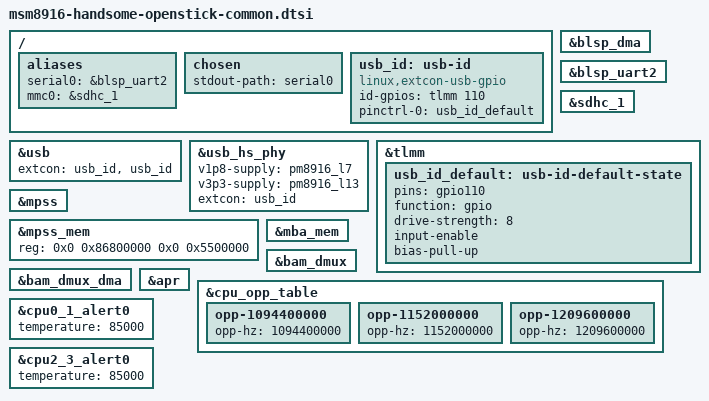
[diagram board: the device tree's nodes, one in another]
// SPDX-License-Identifier: GPL-2.0-only
/*
 * Common definitions for Handsome OpenStick family MSM8916 devices.
 *
 * Based on HandsomeMod 5.10 patches by HandsomeYingyan
 * <handsomeyingyan@gmail.com>, adapted for mainline:
 *   blsp1_uart2 -> blsp_uart2, pronto -> wcnss, msmgpio -> tlmm,
 *   smd_rpm_regulators -> pm8916_rpm_regulators (voltages now upstreamed).
 *
 * Modem is enabled for data only (bam-dmux); voice call services
 * (q6voiced/q6mvm/q6cvp/q6cvs) are not yet available in mainline.
 */

#include "msm8916-pm8916.dtsi"
#include <dt-bindings/gpio/gpio.h>
#include <dt-bindings/input/input.h>

/ {
	aliases {
		serial0 = &blsp_uart2;
		mmc0 = &sdhc_1;
	};

	chosen {
		stdout-path = "serial0";
	};

	usb_id: usb-id {
		compatible = "linux,extcon-usb-gpio";
		id-gpios = <&tlmm 110 GPIO_ACTIVE_HIGH>;
		pinctrl-names = "default";
		pinctrl-0 = <&usb_id_default>;
	};
};

&blsp_dma {
	status = "okay";
};

&blsp_uart2 {
	status = "okay";
};

&sdhc_1 {
	status = "okay";
};

&usb {
	status = "okay";
	extcon = <&usb_id>, <&usb_id>;
};

&usb_hs_phy {
	v1p8-supply = <&pm8916_l7>;
	v3p3-supply = <&pm8916_l13>;
	extcon = <&usb_id>;
};

&tlmm {
	usb_id_default: usb-id-default-state {
		pins = "gpio110";
		function = "gpio";

		drive-strength = <8>;
		input-enable;
		bias-pull-up;
	};
};

/* Modem (Hexagon) for mobile data */
&mpss {
	status = "okay";
};

&mpss_mem {
	/* Mainline dtsi leaves size 0 ("device-specific"): 85MiB as on 5.15 BSP */
	reg = <0x0 0x86800000 0x0 0x5500000>;
	status = "okay";
};

&mba_mem {
	status = "okay";
};

&bam_dmux {
	status = "okay";
};

&bam_dmux_dma {
	status = "okay";
};

&apr {
	status = "okay";
};

/* ----------------------------------------------------------------
 * CPU OC（全员启用，2026-09-16 定稿）
 *
 * A53 PLL 在 998.4 MHz 之上追加三档（1094.4 / 1152 / 1209.6 MHz）。
 * 实测天花板：1209.6 MHz 以上无增益（1401.6 MHz PLL 会动但性能零提升，
 * 纯发热），刻意不暴露。1.30V 固定轨（SAW2 AVS）是频率上限的根源。
 * 被动冷却 75 -> 85 C，110 C critical 仍是硬性安全网；持续负载由
 * thermal governor 自动降档。
 */
&cpu_opp_table {
	opp-1094400000 {
		opp-hz = /bits/ 64 <1094400000>;
	};

	opp-1152000000 {
		opp-hz = /bits/ 64 <1152000000>;
	};

	opp-1209600000 {
		opp-hz = /bits/ 64 <1209600000>;
	};
};

&cpu0_1_alert0 {
	temperature = <85000>;
};

&cpu2_3_alert0 {
	temperature = <85000>;
};
